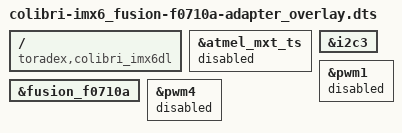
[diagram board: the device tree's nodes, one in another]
// SPDX-License-Identifier: GPL-2.0-or-later OR MIT
/*
 * Copyright 2020-2021 Toradex
 */

// Fusion F0710A touchscreen. Compatible with a Capacitive Touch Adapter.

/dts-v1/;
/plugin/;

/ {
	compatible = "toradex,colibri_imx6dl";
};

&atmel_mxt_ts {
	status = "disabled";
};

&fusion_f0710a {
	status = "okay";
};

&i2c3 {
	status = "okay";
};

&pwm1 {
	status = "disabled";
};

&pwm4{
	status = "disabled";
};
